# PIC32CX1025MTSH128S1 register map
Vendor: Microchip Technology; Series: PIC32CXMTSH; File version: 0
CPU: CM4 r0p1, selectable endian, MPU, FPU, 4 interrupt priority bits
Registers are 32-bit, read-write, reset 0x0 unless marked. A register's access mark holds for its fields unless they carry their own. Offsets are from the block's base; [hi:lo] are bit positions; {n}, {i} and the like mark numbered series.

## SLCDC — Segment LCD Controller
Base 0x40030000; register names take the prefix SLCDC_
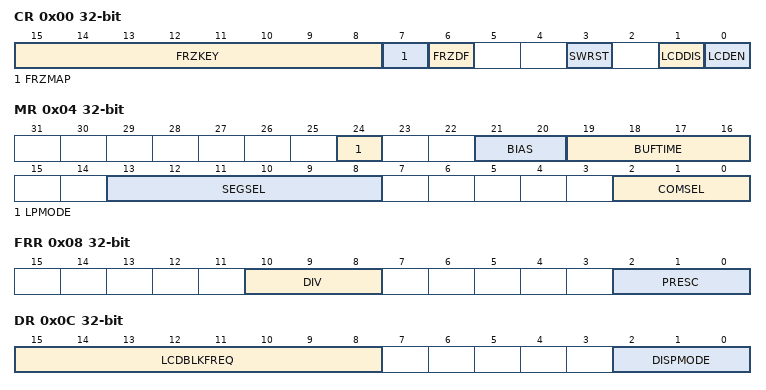
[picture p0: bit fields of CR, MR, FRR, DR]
0x00 CR wo — Control Register
  [15:8] FRZKEY — Freeze Key (write-only)
    78=PASSWD (Writing any other value in this field aborts the write operation of the FRZDF bit or FRZMAP bit. Always reads as 0.)
  [7] FRZMAP — Freeze Remap Configuration
  [6] FRZDF — Freeze Display Panel Features Configuration
  [3] SWRST — Software Reset
  [1] LCDDIS — Disable LCDC
  [0] LCDEN — Enable the LCDC
0x04 MR — Mode Register
  [24] LPMODE — Low-Power Mode
  [21:20] BIAS — LCD Display Configuration
    0=STATIC; 1=BIAS_1_2; 2=BIAS_1_3; 3=BIAS_1_4
  [19:16] BUFTIME — Buffer On-Time
    0=OFF (Nominal drive time is 0% of SLCK period); 1=X2_SLCK_PERIOD (Nominal drive time is 2 periods of SLCK clock); 2=X4_SLCK_PERIOD (Nominal drive time is 4 periods of SLCK clock); 3=X8_SLCK_PERIOD (Nominal drive time is 8 periods of SLCK clock); 4=X16_SLCK_PERIOD (Nominal drive time is 16 periods of SLCK clock); 5=X32_SLCK_PERIOD (Nominal drive time is 32 periods of SLCK clock); 6=X64_SLCK_PERIOD (Nominal drive time is 64 periods of SLCK clock); 7=X128_SLCK_PERIOD (Nominal drive time is 128 periods of SLCK clock); 8=PERCENT_50 (Nominal drive time is 50% of SLCK period); 9=PERCENT_100 (Nominal drive time is 100% of SLCK period)
  [13:8] SEGSEL — Selection of the Number of Segments
  [2:0] COMSEL — Selection of the Number of Commons
    0=COM_0 (COM0 is driven by SLCDC, COM1:7 are driven by digital function); {v}=COM_0TO{v} (COM0:{v} are driven by SLCDC, COM{v+1}:7 are driven by digital function) (v=1..5); 6=COM_0TO6 (COM0:6 are driven by SLCDC, COM7 driven by digital function); 7=COM_0TO7 (COM0:7 are driven by SLCDC, no COM pin driven by digital function)
0x08 FRR — Frame Rate Register
  [10:8] DIV — Clock Division
    {v}=PRESC_CLK_DIV{v+1} (Clock output from prescaler is divided by {v+1}) (v=0..7)
  [2:0] PRESC — Clock Prescaler
    0=SLCK_DIV8 (Slow clock is divided by 8); 1=SLCK_DIV16 (Slow clock is divided by 16); 2=SLCK_DIV32 (Slow clock is divided by 32); 3=SLCK_DIV64 (Slow clock is divided by 64); 4=SLCK_DIV128 (Slow clock is divided by 128); 5=SLCK_DIV256 (Slow clock is divided by 256); 6=SLCK_DIV512 (Slow clock is divided by 512); 7=SLCK_DIV1024 (Slow clock is divided by 1024)
0x0C DR — Display Register
  [15:8] LCDBLKFREQ — LCD Blinking Frequency Selection
  [2:0] DISPMODE — Display Mode Register
    0=NORMAL (Normal Mode-Latched data are displayed.); 1=FORCE_OFF (Force Off Mode-All pixels are invisible. (The SLCDC memory is unchanged.)); 2=FORCE_ON (Force On Mode-All pixels are visible. (The SLCDC memory is unchanged.)); 3=BLINKING (Blinking Mode-All pixels are alternately turned off to the predefined state in SLCDC memory at LCDBLKFREQ frequency. (The SLCDC memory is unchanged.)); 4=INVERTED (Inverted Mode-All pixels are set in the inverted state as defined in SLCDC memory. (The SLCDC memory is unchanged.)); 5=INVERTED_BLINK (Inverted Blinking Mode-All pixels are alternately turned off to the predefined opposite state in SLCDC memory at LCDBLKFREQ frequency. (The SLCDC memory is unchanged.)); 6=USER_BUFFER_LOAD (User Buffer Only Load Mode-Blocks the automatic transfer from User Buffer to Display Buffer.); 7=BUFFERS_SWAP (Buffer Swap Mode-All pixels are alternatively assigned to the state defined in the User Buffer, then to the state defined in the Display Buffer at LCDBLKFREQ frequency.)
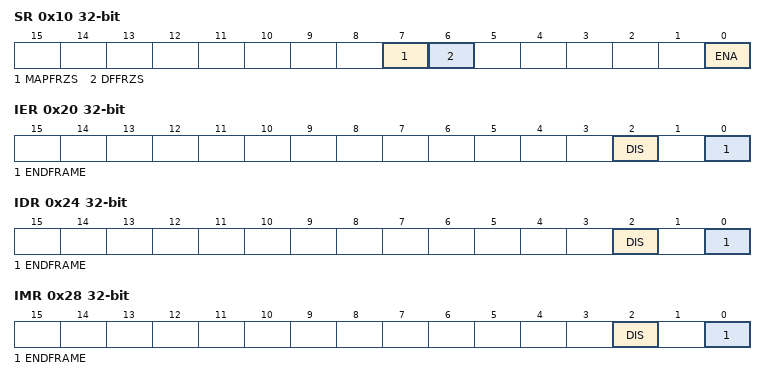
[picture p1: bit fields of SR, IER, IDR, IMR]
0x10 SR ro — Status Register
  [7] MAPFRZS — Remapping Configuration Freeze Status
  [6] DFFRZS — Display Panel Features Configuration Freeze Status
  [0] ENA — Enable Status (Automatically Set/Reset)
0x20 IER wo — Interrupt Enable Register
  [2] DIS — Disable Completion Interrupt Enable
  [0] ENDFRAME — End of Frame Interrupt Enable
0x24 IDR wo — Interrupt Disable Register
  [2] DIS — Disable Completion Interrupt Disable
  [0] ENDFRAME — End of Frame Interrupt Disable
0x28 IMR ro — Interrupt Mask Register
  [2] DIS — Disable Completion Interrupt Mask
  [0] ENDFRAME — End of Frame Interrupt Mask
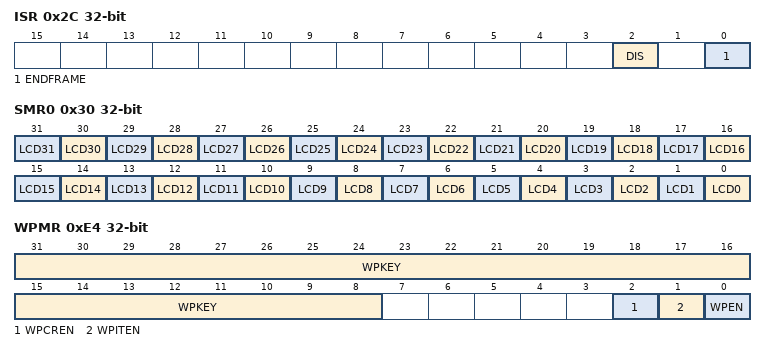
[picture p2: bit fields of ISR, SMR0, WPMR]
0x2C ISR ro — Interrupt Status Register
  [2] DIS — Disable Completion Interrupt Status
  [0] ENDFRAME — End of Frame Interrupt Status
0x30 SMR0 — Segment Map Register 0
  [n] LCD{n} (n=0..31) — LCD Segment Mapped on SEGx I/O Pin
0xE4 WPMR — Write Protection Mode Register
  [31:8] WPKEY — Write Protection Key
    0x534C43=PASSWD (Writing any other value in this field aborts the write operation of the WPEN bit. Always reads as 0.)
  [2] WPCREN — Write Protection Control Enable
  [1] WPITEN — Write Protection Interrupt Enable
  [0] WPEN — Write Protection Enable
{0x200+8i} LMEMR{i} (i=0..7) — LSB Memory Register (com = {i})
  [31:0] LPIXEL — LSB Pixels Pattern Associated to COMx Terminal
